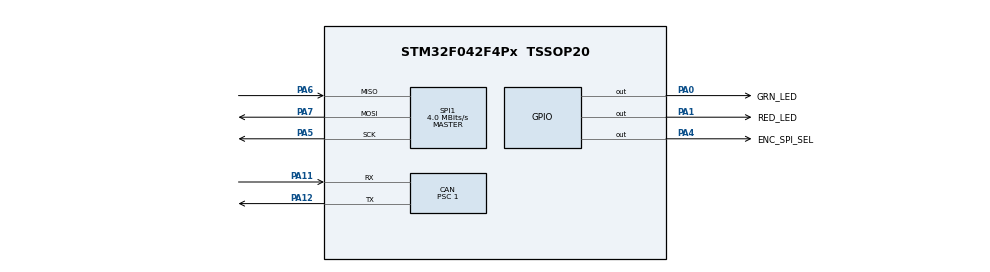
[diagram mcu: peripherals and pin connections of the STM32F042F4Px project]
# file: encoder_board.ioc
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Mcu.Family=STM32F0
VP_SYS_VS_PINREMAP.Mode=PINREMAP
PA6.Mode=Full_Duplex_Master
FREERTOS.Tasks01=defaultTask,24,128,StartDefaultTask,Default,NULL,Dynamic,NULL,NULL
PA7.Mode=Full_Duplex_Master
SPI1.VirtualType=VM_MASTER
CAN.CalculateBaudRate=615384
PA0.GPIO_Label=GRN_LED
PA11.Mode=CAN_Activate
SPI1.CLKPhase=SPI_PHASE_2EDGE
CAN.CalculateTimeBit=1625.00
ProjectManager.StackSize=0x400
VP_FREERTOS_VS_CMSIS_V2.Mode=CMSIS_V2
PA13.Signal=SYS_SWDIO
PA12.Signal=CAN_TX
CAN.BS2=CAN_BS2_4TQ
CAN.Prescaler=1
CAN.BS1=CAN_BS1_8TQ
ProjectManager.TargetToolchain=STM32CubeIDE
SPI1.Direction=SPI_DIRECTION_2LINES
SPI1.CalculateBaudRate=4.0 MBits/s
PA1.Signal=GPIO_Output
PF0-OSC_IN.Mode=HSE-External-Oscillator
PA5.Signal=SPI1_SCK
board=custom
SPI1.Mode=SPI_MODE_MASTER
PA14.Mode=Serial_Wire
VP_SYS_VS_tim1.Mode=TIM1
SPI1.DataSize=SPI_DATASIZE_16BIT
PA1.GPIO_Label=RED_LED
PA13.Mode=Serial_Wire
Mcu.Name=STM32F042F4Px
CAN.CalculateTimeQuantum=125.0
PA0.Signal=GPIO_Output
PA4.Signal=GPIO_Output
NVIC.CEC_CAN_IRQn=true\:3\:0\:false\:false\:true\:true\:true\:true
Mcu.Package=TSSOP20
PA6.Signal=SPI1_MISO
NVIC.TimeBase=TIM1_BRK_UP_TRG_COM_IRQn
PA12.Mode=CAN_Activate
PA11.Signal=CAN_RX
NVIC.TimeBaseIP=TIM1
PA14.Signal=SYS_SWCLK
ProjectManager.HeapSize=0x200
PF0-OSC_IN.Signal=RCC_OSC_IN
PF1-OSC_OUT.Mode=HSE-External-Oscillator
PA4.GPIO_Label=ENC_SPI_SEL
NVIC.TIM1_BRK_UP_TRG_COM_IRQn=true\:0\:0\:false\:false\:true\:false\:false\:true
PF1-OSC_OUT.Signal=RCC_OSC_OUT
PA5.Mode=Full_Duplex_Master
PA7.Signal=SPI1_MOSI

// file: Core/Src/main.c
/* USER CODE BEGIN Header */
/**
  ******************************************************************************
  * @file           : main.c
  * @brief          : Main program body
  ******************************************************************************
  * @attention
  *
  * <h2><center>&copy; Copyright (c) 2021 STMicroelectronics.
  * All rights reserved.</center></h2>
  *
  * This software component is licensed by ST under BSD 3-Clause license,
  * the "License"; You may not use this file except in compliance with the
  * License. You may obtain a copy of the License at:
  *                        opensource.org/licenses/BSD-3-Clause
  *
  ******************************************************************************
  */
/* USER CODE END Header */
#include "main.h"
#include "FreeRTOS.h"
#include "task.h"

CAN_HandleTypeDef hcan;

SPI_HandleTypeDef hspi1;

/* Definitions for defaultTask */

void SystemClock_Config(void);
static void MX_GPIO_Init(void);
static void MX_SPI1_Init(void);
static void MX_CAN_Init(void);
extern void vMainTask(void *argument);

/* USER CODE BEGIN 0 */
uint8_t pxHeap[ configTOTAL_HEAP_SIZE ] __attribute__ ((section ("._user_heap")));
/* USER CODE END 0 */

int main(void)
{

  /* MCU Configuration--------------------------------------------------------*/

  /* Reset of all peripherals, Initializes the Flash interface and the Systick. */
  HAL_Init();

  /* Configure the system clock */
  SystemClock_Config();

  /* Initialize all configured peripherals */
  MX_GPIO_Init();
  MX_SPI1_Init();
  MX_CAN_Init();
  /* USER CODE BEGIN 2 */
  HeapRegion_t regions[2] =
		  {
				  {
						  .pucStartAddress = pxHeap,
						  .xSizeInBytes = sizeof(pxHeap)
				  },
				  {
						  .pucStartAddress = NULL,
						  .xSizeInBytes = 0
				  }
		  };
  vPortDefineHeapRegions( regions );
  /* USER CODE END 2 */

  /* Init scheduler */

  /* Create the thread(s) */
  /* creation of defaultTask */
  main_task_args args = { .pxCAN_Hdl = &hcan,
                          .pxSPI_Hdl = &hspi1 };

  xTaskCreate( vMainTask,
		       "vMainTask",
			   64,
		  	   &args,
			   tskIDLE_PRIORITY,
  	  	  	   NULL );

  /* Start scheduler */
  vTaskStartScheduler();

  /* We should never get here as control is now taken by the scheduler */
  /* Infinite loop */
  while (1)
  {

  }
}

void SystemClock_Config(void)
{
  RCC_OscInitTypeDef RCC_OscInitStruct = {0};
  RCC_ClkInitTypeDef RCC_ClkInitStruct = {0};

  /** Initializes the RCC Oscillators according to the specified parameters
  * in the RCC_OscInitTypeDef structure.
  */
  RCC_OscInitStruct.OscillatorType = RCC_OSCILLATORTYPE_HSI;
  RCC_OscInitStruct.HSIState = RCC_HSI_ON;
  RCC_OscInitStruct.HSICalibrationValue = RCC_HSICALIBRATION_DEFAULT;
  RCC_OscInitStruct.PLL.PLLState = RCC_PLL_NONE;
  if (HAL_RCC_OscConfig(&RCC_OscInitStruct) != HAL_OK)
  {
    Error_Handler();
  }
  /** Initializes the CPU, AHB and APB buses clocks
  */
  RCC_ClkInitStruct.ClockType = RCC_CLOCKTYPE_HCLK|RCC_CLOCKTYPE_SYSCLK
                              |RCC_CLOCKTYPE_PCLK1;
  RCC_ClkInitStruct.SYSCLKSource = RCC_SYSCLKSOURCE_HSI;
  RCC_ClkInitStruct.AHBCLKDivider = RCC_SYSCLK_DIV1;
  RCC_ClkInitStruct.APB1CLKDivider = RCC_HCLK_DIV1;

  if (HAL_RCC_ClockConfig(&RCC_ClkInitStruct, FLASH_LATENCY_0) != HAL_OK)
  {
    Error_Handler();
  }
}

static void MX_CAN_Init(void)
{

  hcan.Instance = CAN;
  hcan.Init.Prescaler = 1;
  hcan.Init.Mode = CAN_MODE_NORMAL;
  hcan.Init.SyncJumpWidth = CAN_SJW_1TQ;
  hcan.Init.TimeSeg1 = CAN_BS1_8TQ;
  hcan.Init.TimeSeg2 = CAN_BS2_4TQ;
  hcan.Init.TimeTriggeredMode = DISABLE;
  hcan.Init.AutoBusOff = DISABLE;
  hcan.Init.AutoWakeUp = DISABLE;
  hcan.Init.AutoRetransmission = DISABLE;
  hcan.Init.ReceiveFifoLocked = DISABLE;
  hcan.Init.TransmitFifoPriority = DISABLE;
  if (HAL_CAN_Init(&hcan) != HAL_OK)
  {
    Error_Handler();
  }

}

static void MX_SPI1_Init(void)
{

  /* SPI1 parameter configuration*/
  hspi1.Instance = SPI1;
  hspi1.Init.Mode = SPI_MODE_MASTER;
  hspi1.Init.Direction = SPI_DIRECTION_2LINES;
  hspi1.Init.DataSize = SPI_DATASIZE_16BIT;
  hspi1.Init.CLKPolarity = SPI_POLARITY_LOW;
  hspi1.Init.CLKPhase = SPI_PHASE_2EDGE;
  hspi1.Init.NSS = SPI_NSS_SOFT;
  hspi1.Init.BaudRatePrescaler = SPI_BAUDRATEPRESCALER_2;
  hspi1.Init.FirstBit = SPI_FIRSTBIT_MSB;
  hspi1.Init.TIMode = SPI_TIMODE_DISABLE;
  hspi1.Init.CRCCalculation = SPI_CRCCALCULATION_DISABLE;
  hspi1.Init.CRCPolynomial = 7;
  hspi1.Init.CRCLength = SPI_CRC_LENGTH_DATASIZE;
  hspi1.Init.NSSPMode = SPI_NSS_PULSE_DISABLE;
  if (HAL_SPI_Init(&hspi1) != HAL_OK)
  {
    Error_Handler();
  }

}

static void MX_GPIO_Init(void)
{
  GPIO_InitTypeDef GPIO_InitStruct = {0};

  /* GPIO Ports Clock Enable */
  __HAL_RCC_GPIOF_CLK_ENABLE();
  __HAL_RCC_GPIOA_CLK_ENABLE();

  /*Configure GPIO pin Output Level */
  HAL_GPIO_WritePin(GPIOA, GRN_LED_Pin|RED_LED_Pin|ENC_SPI_SEL_Pin, GPIO_PIN_RESET);

  /*Configure GPIO pins : GRN_LED_Pin RED_LED_Pin ENC_SPI_SEL_Pin */
  GPIO_InitStruct.Pin = GRN_LED_Pin|RED_LED_Pin|ENC_SPI_SEL_Pin;
  GPIO_InitStruct.Mode = GPIO_MODE_OUTPUT_PP;
  GPIO_InitStruct.Pull = GPIO_NOPULL;
  GPIO_InitStruct.Speed = GPIO_SPEED_FREQ_LOW;
  HAL_GPIO_Init(GPIOA, &GPIO_InitStruct);

}

 /**
  * @brief  Period elapsed callback in non blocking mode
  * @note   This function is called  when TIM1 interrupt took place, inside
  * HAL_TIM_IRQHandler(). It makes a direct call to HAL_IncTick() to increment
  * a global variable "uwTick" used as application time base.
  * @param  htim : TIM handle
  * @retval None
  */
void HAL_TIM_PeriodElapsedCallback(TIM_HandleTypeDef *htim)
{
  if (htim->Instance == TIM1) {
    HAL_IncTick();
  }
}

void Error_Handler(void)
{
  __disable_irq();
  while (1)
  {
  }
}

/************************ (C) COPYRIGHT STMicroelectronics *****END OF FILE****/
